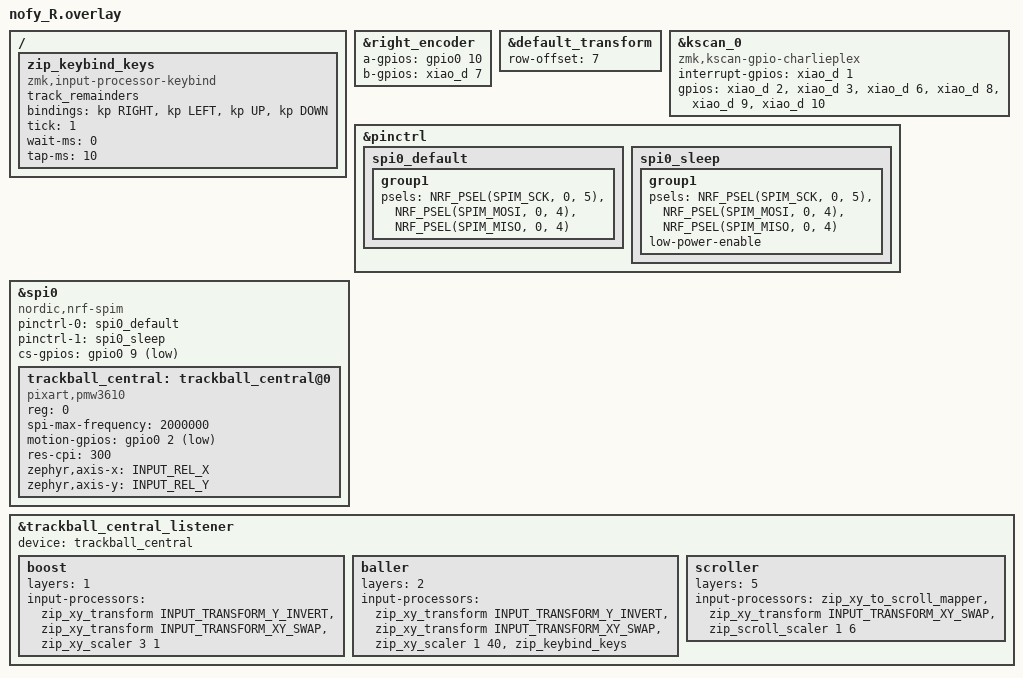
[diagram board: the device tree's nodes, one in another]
#include "nofy.dtsi"
#include <input/processors.dtsi>
#include <zephyr/dt-bindings/input/input-event-codes.h>
#include <input/processors/zmk-input-processor-keybind.dtsi>

&right_encoder {
    status = "okay";
    a-gpios = <&gpio0 10 (GPIO_ACTIVE_HIGH | GPIO_PULL_UP)>;
    b-gpios = <&xiao_d 7 (GPIO_ACTIVE_HIGH | GPIO_PULL_UP)>;
};

&default_transform {
    row-offset = <7>;
};

&kscan_0 {
    compatible = "zmk,kscan-gpio-charlieplex";
    interrupt-gpios = <&xiao_d 1 (GPIO_ACTIVE_HIGH | GPIO_PULL_DOWN)>;
    gpios
        = <&xiao_d 2 GPIO_ACTIVE_HIGH>
        , <&xiao_d 3 GPIO_ACTIVE_HIGH>
        , <&xiao_d 6 GPIO_ACTIVE_HIGH>
        , <&xiao_d 8 GPIO_ACTIVE_HIGH>
        , <&xiao_d 9 GPIO_ACTIVE_HIGH>
        , <&xiao_d 10 GPIO_ACTIVE_HIGH>
        ;
};

&pinctrl {
    spi0_default: spi0_default {
        group1 {
            psels = <NRF_PSEL(SPIM_SCK, 0, 5)>,
                <NRF_PSEL(SPIM_MOSI, 0, 4)>,
                <NRF_PSEL(SPIM_MISO, 0, 4)>;
        };
    };

    spi0_sleep: spi0_sleep {
        group1 {
            psels = <NRF_PSEL(SPIM_SCK, 0, 5)>,
                <NRF_PSEL(SPIM_MOSI, 0, 4)>,
                <NRF_PSEL(SPIM_MISO, 0, 4)>;
            low-power-enable;
        };
    };
};

&spi0 {
    status = "okay";
    compatible = "nordic,nrf-spim";
    pinctrl-0 = <&spi0_default>;
    pinctrl-1 = <&spi0_sleep>;
    pinctrl-names = "default", "sleep";
    cs-gpios = <&gpio0 9 GPIO_ACTIVE_LOW>;

    trackball_central: trackball_central@0 {
        status = "okay";
        compatible = "pixart,pmw3610";
        reg = <0>;
        spi-max-frequency = <2000000>;
        motion-gpios = <&gpio0 2 (GPIO_ACTIVE_LOW | GPIO_PULL_UP)>;
        res-cpi = <300>;
        zephyr,axis-x = <INPUT_REL_X>;
        zephyr,axis-y = <INPUT_REL_Y>;
    };
};

/ {
    zip_keybind_keys: zip_keybind_keys {
        compatible = "zmk,input-processor-keybind";
        #input-processor-cells = <0>;
        track_remainders;
        bindings = <&kp RIGHT>,
                  <&kp LEFT>,
                  <&kp UP>,
                  <&kp DOWN>;
        tick = <1>;
        wait-ms = <0>;
        tap-ms = <10>;
        // mode = <1>
        // threshold = <10>
        // max_threshold = <200>
        // max_pending_activations = <10>
    };
};

&trackball_central_listener {
    status = "okay";
    device = <&trackball_central>;

    boost {
        layers = <1>;
        input-processors = <
            &zip_xy_transform INPUT_TRANSFORM_Y_INVERT
            &zip_xy_transform INPUT_TRANSFORM_XY_SWAP
            &zip_xy_scaler 3 1
        >;
    };

    baller {
        layers = <2>;
        input-processors = <
            &zip_xy_transform INPUT_TRANSFORM_Y_INVERT
            &zip_xy_transform INPUT_TRANSFORM_XY_SWAP
            &zip_xy_scaler 1 40
            &zip_keybind_keys
        >;
    };

    scroller {
        layers = <5>;
        input-processors = <
            &zip_xy_to_scroll_mapper
            &zip_xy_transform INPUT_TRANSFORM_XY_SWAP
            &zip_scroll_scaler 1 6
        >;
    };
};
